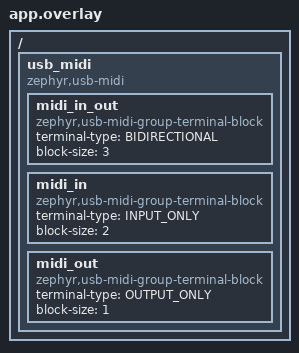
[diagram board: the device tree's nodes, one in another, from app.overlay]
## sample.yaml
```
sample:
  name: MIDI USB
tests:
  sample.usb_device_next.midi:
    depends_on: usbd
    tags: usb
    integration_platforms:
      - nrf52840dk/nrf52840
      - nrf54h20dk/nrf54h20/cpuapp
      - frdm_k64f
      - stm32f723e_disco
      - nucleo_f413zh
      - mimxrt685_evk/mimxrt685s/cm33
      - mimxrt1060_evk
    harness: console
    harness_config:
      type: one_line
      regex:
        - "Wait for DTR"
  sample.usb.cdc-acm.buildonly:
    depends_on: usbd
    tags: usb
    arch_allow: posix
    build_only: true
    integration_platforms:
      - native_sim
```

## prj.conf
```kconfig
CONFIG_USB_DEVICE_STACK_NEXT=y
CONFIG_USBD_MIDI_CLASS=y

CONFIG_SAMPLE_USBD_PRODUCT="USBD MIDI Sample"
CONFIG_SAMPLE_USBD_PID=0x0001

CONFIG_LOG=y
CONFIG_USBD_LOG_LEVEL_WRN=y
CONFIG_UDC_DRIVER_LOG_LEVEL_WRN=y

CONFIG_INPUT=y
CONFIG_SHELL=y

CONFIG_USBD_SHELL=y
CONFIG_USBD_MIDI_LOG_LEVEL_DBG=y
```

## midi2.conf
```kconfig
CONFIG_USBD_MIDI_CLASS_MIDI2=y
```

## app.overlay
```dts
/*
 * Copyright (c) 2024 Titouan Christophe
 *
 * SPDX-License-Identifier: Apache-2.0
 */

 #include <dt-bindings/usb/midi.h>

/ {
	usb_midi: usb_midi {
		compatible = "zephyr,usb-midi";
		status = "okay";

		/* 48 channels in/out port */
		midi_in_out {
			compatible = "zephyr,usb-midi-group-terminal-block";
			terminal-type = <BIDIRECTIONAL>;
			block-size = <3>;
		};

		/* 32 channels in port */
		midi_in {
			compatible = "zephyr,usb-midi-group-terminal-block";
			terminal-type = <INPUT_ONLY>;
			block-size = <2>;
		};

		/* 16 channels out port */
		midi_out {
			compatible = "zephyr,usb-midi-group-terminal-block";
			terminal-type = <OUTPUT_ONLY>;
			block-size = <1>;
		};
	};
};
```

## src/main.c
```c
/*
 * Copyright (c) 2024 Titouan Christophe
 *
 * SPDX-License-Identifier: Apache-2.0
 *
 * @file
 * @brief Sample application for USB MIDI 2.0 device class
 */

#include <sample_usbd.h>

#include <zephyr/device.h>
#include <zephyr/drivers/gpio.h>
#include <zephyr/input/input.h>
#include <zephyr/usb/class/midi.h>
#include <zephyr/usb/class/usbd_midi.h>

#include <zephyr/logging/log.h>
LOG_MODULE_REGISTER(sample_usb_midi, LOG_LEVEL_INF);

static const struct device *const midi = DEVICE_DT_GET(DT_NODELABEL(usb_midi));

static struct gpio_dt_spec led = GPIO_DT_SPEC_GET_OR(DT_ALIAS(led0), gpios, {0});

static void key_press(struct input_event *evt, void *user_data)
{
	/* Only handle key presses in the 7bit MIDI range */
	if (evt->type != INPUT_EV_KEY || evt->code > 0x7f) {
		return;
	}
	uint8_t command = evt->value ? UMP_MIDI_NOTE_ON : UMP_MIDI_NOTE_OFF;
	uint8_t channel = 0;
	uint8_t note = evt->code;
	uint8_t velocity = 100;

	struct midi_ump ump = UMP_MIDI1_CHANNEL_VOICE(0, command, channel,
						      note, velocity);
	usbd_midi_send(midi, &ump);
}
INPUT_CALLBACK_DEFINE(NULL, key_press, NULL);

static void on_midi_packet(const struct device *dev, const struct midi_ump *ump)
{
	LOG_INF("Received MIDI packet (MT=%X)", UMP_MT(ump));

	/* Only send MIDI1 channel voice messages back to the host */
	if (UMP_MT(ump) == UMP_MT_MIDI1_CHANNEL_VOICE) {
		LOG_INF("Send back MIDI1 message %02X %02X %02X", UMP_MIDI_STATUS(ump),
			UMP_MIDI1_P1(ump), UMP_MIDI1_P2(ump));
		usbd_midi_send(dev, ump);
	}
}

static void on_status_change(const struct device *dev, enum usbd_midi_status st)
{
	/* Light up the LED (if any) when USB-MIDI2.0 is enabled */
	if (led.port) {
		gpio_pin_set_dt(&led, st == USBD_MIDI_2_ENABLED);
	}
}

static const struct usbd_midi_ops ops = {
	.rx_packet_cb = on_midi_packet,
	.status_change_cb = on_status_change,
};

int main(void)
{
	struct usbd_context *sample_usbd;

	if (!device_is_ready(midi)) {
		LOG_ERR("MIDI device not ready");
		return -1;
	}

	if (led.port) {
		if (gpio_pin_configure_dt(&led, GPIO_OUTPUT)) {
			LOG_ERR("Unable to setup LED, not using it");
			memset(&led, 0, sizeof(led));
		}
	}

	usbd_midi_set_ops(midi, &ops);

	sample_usbd = sample_usbd_init_device(NULL);
	if (sample_usbd == NULL) {
		LOG_ERR("Failed to initialize USB device");
		return -1;
	}

	if (usbd_enable(sample_usbd)) {
		LOG_ERR("Failed to enable device support");
		return -1;
	}

	LOG_INF("USB device support enabled");
	return 0;
}
```
